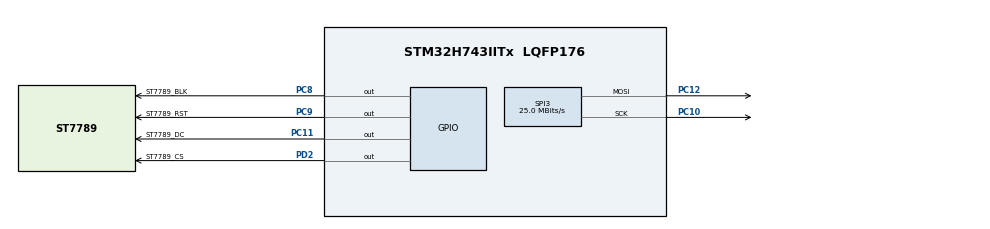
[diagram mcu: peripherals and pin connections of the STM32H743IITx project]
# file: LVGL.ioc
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CORTEX_M7.default_mode_Activation=1
Dma.Request0=SPI3_TX
Dma.SPI3_TX.0.Direction=DMA_MEMORY_TO_PERIPH
Dma.SPI3_TX.0.EventEnable=DISABLE
Dma.SPI3_TX.0.FIFOMode=DMA_FIFOMODE_DISABLE
Dma.SPI3_TX.0.Instance=DMA1_Stream0
Dma.SPI3_TX.0.MemDataAlignment=DMA_MDATAALIGN_BYTE
Dma.SPI3_TX.0.MemInc=DMA_MINC_ENABLE
Dma.SPI3_TX.0.Mode=DMA_NORMAL
Dma.SPI3_TX.0.PeriphDataAlignment=DMA_PDATAALIGN_BYTE
Dma.SPI3_TX.0.PeriphInc=DMA_PINC_DISABLE
Dma.SPI3_TX.0.Polarity=HAL_DMAMUX_REQ_GEN_RISING
Dma.SPI3_TX.0.Priority=DMA_PRIORITY_LOW
Dma.SPI3_TX.0.RequestNumber=1
Dma.SPI3_TX.0.SignalID=NONE
Dma.SPI3_TX.0.SyncEnable=DISABLE
Dma.SPI3_TX.0.SyncPolarity=HAL_DMAMUX_SYNC_NO_EVENT
Dma.SPI3_TX.0.SyncRequestNumber=1
Dma.SPI3_TX.0.SyncSignalID=NONE
Mcu.Family=STM32H7
Mcu.Name=STM32H743IITx
Mcu.Package=LQFP176
NVIC.DMA1_Stream0_IRQn=true\:0\:0\:false\:false\:true\:false\:true\:true
NVIC.PriorityGroup=NVIC_PRIORITYGROUP_4
NVIC.SPI3_IRQn=true\:0\:0\:false\:false\:true\:false\:true\:true
PA13\ (JTMS/SWDIO).Mode=JTAG_5_pins
PA13\ (JTMS/SWDIO).Signal=DEBUG_JTMS-SWDIO
PA14\ (JTCK/SWCLK).Mode=JTAG_5_pins
PA14\ (JTCK/SWCLK).Signal=DEBUG_JTCK-SWCLK
PA15\ (JTDI).Mode=JTAG_5_pins
PA15\ (JTDI).Signal=DEBUG_JTDI
PB3\ (JTDO/TRACESWO).Mode=JTAG_5_pins
PB3\ (JTDO/TRACESWO).Signal=DEBUG_JTDO-SWO
PB4\ (NJTRST).Mode=JTAG_5_pins
PB4\ (NJTRST).Signal=DEBUG_JTRST
PC10.Mode=TX_Only_Simplex_Unidirect_Master
PC10.Signal=SPI3_SCK
PC11.GPIO_Label=ST7789_DC
PC11.Signal=GPIO_Output
PC12.Mode=TX_Only_Simplex_Unidirect_Master
PC12.Signal=SPI3_MOSI
PC8.GPIO_Label=ST7789_BLK
PC8.Signal=GPIO_Output
PC9.GPIO_Label=ST7789_RST
PC9.Signal=GPIO_Output
PD2.GPIO_Label=ST7789_CS
PD2.Signal=GPIO_Output
PH0-OSC_IN\ (PH0).Mode=HSE-External-Oscillator
PH0-OSC_IN\ (PH0).Signal=RCC_OSC_IN
PH1-OSC_OUT\ (PH1).Mode=HSE-External-Oscillator
PH1-OSC_OUT\ (PH1).Signal=RCC_OSC_OUT
ProjectManager.HeapSize=0x8000
ProjectManager.StackSize=0x8000
ProjectManager.TargetToolchain=MDK-ARM V5.32
RCC.ADCFreq_Value=50390625
RCC.APB1Freq_Value=118750000
RCC.APB2Freq_Value=118750000
RCC.APB3Freq_Value=118750000
RCC.APB4Freq_Value=118750000
RCC.CortexFreq_Value=475000000
RCC.D1PPRE=RCC_APB3_DIV2
RCC.D2PPRE1=RCC_APB1_DIV2
RCC.D2PPRE2=RCC_APB2_DIV2
RCC.D3PPRE=RCC_APB4_DIV2
RCC.DIVM1=2
RCC.DIVN1=76
RCC.DIVQ1=19
RCC.EnbaleCSS=true
RCC.HCLKFreq_Value=237500000
RCC.HPRE=RCC_HCLK_DIV2
RCC.PLLSourceVirtual=RCC_PLLSOURCE_HSE
RCC.SYSCLKFreq_VALUE=475000000
RCC.SYSCLKSource=RCC_SYSCLKSOURCE_PLLCLK
RCC.USBFreq_Value=50000000
SPI3.BaudRatePrescaler=SPI_BAUDRATEPRESCALER_2
SPI3.CLKPolarity=SPI_POLARITY_HIGH
SPI3.CalculateBaudRate=25.0 MBits/s
SPI3.DataSize=SPI_DATASIZE_8BIT
SPI3.Direction=SPI_DIRECTION_2LINES_TXONLY
SPI3.Mode=SPI_MODE_MASTER
SPI3.VirtualType=VM_MASTER
board=custom

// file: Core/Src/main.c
/* USER CODE BEGIN Header */
/**
  ******************************************************************************
  * @file           : main.c
  * @brief          : Main program body
  ******************************************************************************
  * @attention
  *
  * Copyright (c) 2024 STMicroelectronics.
  * All rights reserved.
  *
  * This software is licensed under terms that can be found in the LICENSE file
  * in the root directory of this software component.
  * If no LICENSE file comes with this software, it is provided AS-IS.
  *
  ******************************************************************************
  */
/* USER CODE END Header */
#include "main.h"
#include "dma.h"
#include "spi.h"
#include "gpio.h"

/* USER CODE BEGIN Includes */
#include "st7789.h"
#include "lv_port_disp_template.h"
#include "../../demos/benchmark/lv_demo_benchmark.h"
/* USER CODE END Includes */

void SystemClock_Config(void);
static void MPU_Config(void);

int main(void)
{

  /* MPU Configuration--------------------------------------------------------*/
  MPU_Config();

  /* MCU Configuration--------------------------------------------------------*/

  /* Reset of all peripherals, Initializes the Flash interface and the Systick. */
  HAL_Init();

  /* Configure the system clock */
  SystemClock_Config();

  /* Initialize all configured peripherals */
  MX_GPIO_Init();
  MX_DMA_Init();
  MX_SPI3_Init();
  /* USER CODE BEGIN 2 */
	lv_init();
	lv_port_disp_init();
	lv_demo_benchmark();
//	lv_demo_widgets();
  /* USER CODE END 2 */

  /* Infinite loop */
  /* USER CODE BEGIN WHILE */
  while (1)
  {
		lv_tick_inc(1);
		lv_task_handler();
    /* USER CODE END WHILE */

  }
}

void SystemClock_Config(void)
{
  RCC_OscInitTypeDef RCC_OscInitStruct = {0};
  RCC_ClkInitTypeDef RCC_ClkInitStruct = {0};

  /** Supply configuration update enable
  */
  HAL_PWREx_ConfigSupply(PWR_LDO_SUPPLY);

  /** Configure the main internal regulator output voltage
  */
  __HAL_PWR_VOLTAGESCALING_CONFIG(PWR_REGULATOR_VOLTAGE_SCALE1);

  while(!__HAL_PWR_GET_FLAG(PWR_FLAG_VOSRDY)) {}

  __HAL_RCC_SYSCFG_CLK_ENABLE();
  __HAL_PWR_VOLTAGESCALING_CONFIG(PWR_REGULATOR_VOLTAGE_SCALE0);

  while(!__HAL_PWR_GET_FLAG(PWR_FLAG_VOSRDY)) {}

  /** Initializes the RCC Oscillators according to the specified parameters
  * in the RCC_OscInitTypeDef structure.
  */
  RCC_OscInitStruct.OscillatorType = RCC_OSCILLATORTYPE_HSE;
  RCC_OscInitStruct.HSEState = RCC_HSE_ON;
  RCC_OscInitStruct.PLL.PLLState = RCC_PLL_ON;
  RCC_OscInitStruct.PLL.PLLSource = RCC_PLLSOURCE_HSE;
  RCC_OscInitStruct.PLL.PLLM = 2;
  RCC_OscInitStruct.PLL.PLLN = 76;
  RCC_OscInitStruct.PLL.PLLP = 2;
  RCC_OscInitStruct.PLL.PLLQ = 19;
  RCC_OscInitStruct.PLL.PLLR = 2;
  RCC_OscInitStruct.PLL.PLLRGE = RCC_PLL1VCIRANGE_3;
  RCC_OscInitStruct.PLL.PLLVCOSEL = RCC_PLL1VCOWIDE;
  RCC_OscInitStruct.PLL.PLLFRACN = 0;
  if (HAL_RCC_OscConfig(&RCC_OscInitStruct) != HAL_OK)
  {
    Error_Handler();
  }

  /** Initializes the CPU, AHB and APB buses clocks
  */
  RCC_ClkInitStruct.ClockType = RCC_CLOCKTYPE_HCLK|RCC_CLOCKTYPE_SYSCLK
                              |RCC_CLOCKTYPE_PCLK1|RCC_CLOCKTYPE_PCLK2
                              |RCC_CLOCKTYPE_D3PCLK1|RCC_CLOCKTYPE_D1PCLK1;
  RCC_ClkInitStruct.SYSCLKSource = RCC_SYSCLKSOURCE_PLLCLK;
  RCC_ClkInitStruct.SYSCLKDivider = RCC_SYSCLK_DIV1;
  RCC_ClkInitStruct.AHBCLKDivider = RCC_HCLK_DIV2;
  RCC_ClkInitStruct.APB3CLKDivider = RCC_APB3_DIV2;
  RCC_ClkInitStruct.APB1CLKDivider = RCC_APB1_DIV2;
  RCC_ClkInitStruct.APB2CLKDivider = RCC_APB2_DIV2;
  RCC_ClkInitStruct.APB4CLKDivider = RCC_APB4_DIV2;

  if (HAL_RCC_ClockConfig(&RCC_ClkInitStruct, FLASH_LATENCY_4) != HAL_OK)
  {
    Error_Handler();
  }

  /** Enables the Clock Security System
  */
  HAL_RCC_EnableCSS();
}

 /* MPU Configuration */

void MPU_Config(void)
{
  MPU_Region_InitTypeDef MPU_InitStruct = {0};

  /* Disables the MPU */
  HAL_MPU_Disable();

  /** Initializes and configures the Region and the memory to be protected
  */
  MPU_InitStruct.Enable = MPU_REGION_ENABLE;
  MPU_InitStruct.Number = MPU_REGION_NUMBER0;
  MPU_InitStruct.BaseAddress = 0x0;
  MPU_InitStruct.Size = MPU_REGION_SIZE_4GB;
  MPU_InitStruct.SubRegionDisable = 0x87;
  MPU_InitStruct.TypeExtField = MPU_TEX_LEVEL0;
  MPU_InitStruct.AccessPermission = MPU_REGION_NO_ACCESS;
  MPU_InitStruct.DisableExec = MPU_INSTRUCTION_ACCESS_DISABLE;
  MPU_InitStruct.IsShareable = MPU_ACCESS_SHAREABLE;
  MPU_InitStruct.IsCacheable = MPU_ACCESS_NOT_CACHEABLE;
  MPU_InitStruct.IsBufferable = MPU_ACCESS_NOT_BUFFERABLE;

  HAL_MPU_ConfigRegion(&MPU_InitStruct);
  /* Enables the MPU */
  HAL_MPU_Enable(MPU_PRIVILEGED_DEFAULT);

}

void Error_Handler(void)
{
  __disable_irq();
  while (1)
  {
  }
}
